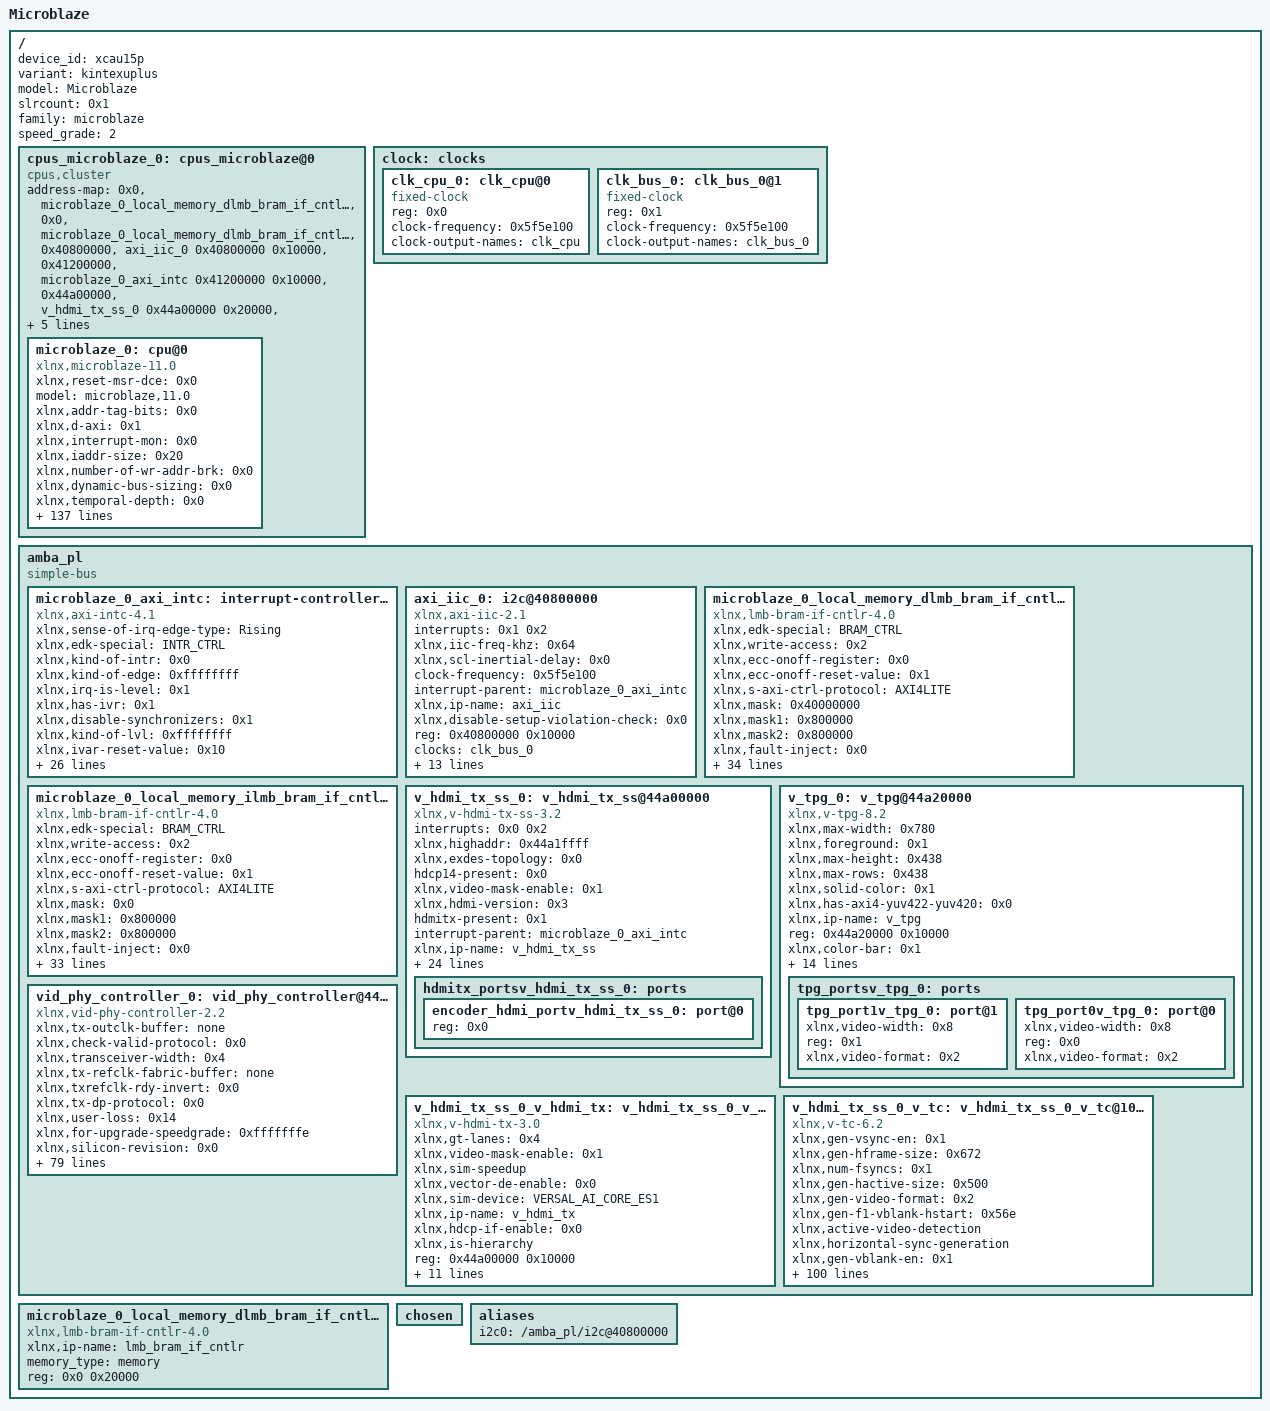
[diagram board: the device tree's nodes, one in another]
/dts-v1/;
/ {
        device_id = "xcau15p";
        #address-cells = <0x1>;
        variant = "kintexuplus";
        model = "Microblaze";
        #size-cells = <0x1>;
        slrcount = <0x1>;
        family = "microblaze";
        speed_grade = "2";

        cpus_microblaze_0: cpus_microblaze@0 {
                phandle = <0xc>;
                #cpu-mask-cells = <0x1>;
                compatible = "cpus,cluster";
                #address-cells = <0x1>;
                #size-cells = <0x0>;
                address-map = <0x0 &microblaze_0_local_memory_dlmb_bram_if_cntlr_memory 0x0 0x20000>,
                 <0x0 &microblaze_0_local_memory_dlmb_bram_if_cntlr 0x0 0x20000>,
                 <0x40800000 &axi_iic_0 0x40800000 0x10000>,
                 <0x41200000 &microblaze_0_axi_intc 0x41200000 0x10000>,
                 <0x44a00000 &v_hdmi_tx_ss_0 0x44a00000 0x20000>,
                 <0x44a20000 &v_tpg_0 0x44a20000 0x10000>,
                 <0x44a30000 &vid_phy_controller_0 0x44a30000 0x10000>,
                 <0x0 &v_hdmi_tx_ss_0_v_hdmi_tx 0x0 0x10000>,
                 <0x10000 &v_hdmi_tx_ss_0_v_tc 0x10000 0x10000>;
                #ranges-address-cells = <0x1>;
                #ranges-size-cells = <0x1>;

                microblaze_0: cpu@0 {
                        phandle = <0xd>;
                        xlnx,reset-msr-dce = <0x0>;
                        model = "microblaze,11.0";
                        xlnx,addr-tag-bits = <0x0>;
                        xlnx,d-axi = <0x1>;
                        xlnx,interrupt-mon = <0x0>;
                        xlnx,iaddr-size = <0x20>;
                        xlnx,number-of-wr-addr-brk = <0x0>;
                        xlnx,dynamic-bus-sizing = <0x0>;
                        xlnx,temporal-depth = <0x0>;
                        xlnx,use-interrupt = <0x2>;
                        xlnx,optimization = <0x0>;
                        xlnx,ip-axi-mon = <0x0>;
                        xlnx,ip-name = "microblaze";
                        d-cache-highaddr = <0x3fffffff>;
                        xlnx,dcache-force-tag-lutram = <0x0>;
                        xlnx,pc-width = <0x20>;
                        xlnx,interrupt-is-edge = <0x0>;
                        reg = <0x0>;
                        xlnx,async-interrupt = <0x1>;
                        xlnx,use-mmu = <0x0>;
                        xlnx,reset-msr-ee = <0x0>;
                        xlnx,icache-victims = <0x0>;
                        xlnx,use-reorder-instr = <0x0>;
                        xlnx,d-lmb-mon = <0x0>;
                        xlnx,d-lmb-protocol = <0x0>;
                        xlnx,ill-opcode-exception = <0x0>;
                        xlnx,dcache-always-used = <0x0>;
                        xlnx,use-div = <0x0>;
                        xlnx,dc-axi-mon = <0x0>;
                        xlnx,debug-trace-async-reset = <0x0>;
                        xlnx,trace = <0x0>;
                        xlnx,part = "xcau15p-ffvb676-2-e";
                        i-cache-baseaddr = <0x0>;
                        xlnx,use-config-reset = <0x0>;
                        xlnx,pvr = <0x0>;
                        xlnx,i-lmb-mon = <0x0>;
                        xlnx,dcache-byte-size = <0x1000>;
                        xlnx,fault-tolerant = <0x0>;
                        xlnx,family = "kintexuplus";
                        compatible = "xlnx,microblaze-11.0", "xlnx,microblaze";
                        xlnx,data-size = <0x20>;
                        xlnx,mmu-zones = <0x2>;
                        xlnx,debug-trace-size = <0x2000>;
                        xlnx,mmu-privileged-instr = <0x0>;
                        xlnx,enable-discrete-ports = <0x0>;
                        d-cache-line-size = <0x10>;
                        xlnx,d-lmb = <0x1>;
                        xlnx,sco = <0x0>;
                        xlnx,reset-msr-eip = <0x0>;
                        xlnx,debug-interface = <0x0>;
                        clock-frequency = <0x5f5e100>;
                        xlnx,use-ext-brk = <0x0>;
                        xlnx,daddr-size = <0x20>;
                        xlnx,debug-enabled = <0x1>;
                        xlnx,reset-msr-ice = <0x0>;
                        xlnx,num-sync-ff-dbg-trace-clk = <0x2>;
                        xlnx,i-lmb-protocol = <0x0>;
                        xlnx,endianness = <0x1>;
                        xlnx,fsl-exception = <0x0>;
                        i-cache-line-size = <0x10>;
                        xlnx,use-extended-fsl-instr = <0x0>;
                        xlnx,reset-msr = <0x0>;
                        xlnx,dp-axi-mon = <0x0>;
                        device_type = "cpu";
                        xlnx,branch-target-cache-size = <0x0>;
                        xlnx,dcache-use-writeback = <0x0>;
                        xlnx,div-zero-exception = <0x0>;
                        xlnx,mmu-tlb-access = <0x3>;
                        bus-handle = <&amba_pl>;
                        xlnx,cache-byte-size = <0x1000>;
                        xlnx,pvr-user2 = <0x0>;
                        xlnx,opcode-0x0-illegal = <0x0>;
                        xlnx,icache-line-len = <0x4>;
                        xlnx,ecc-use-ce-exception = <0x0>;
                        xlnx,base-vectors = <0x0>;
                        xlnx,d-lmb-has-prot = <0x0>;
                        xlnx,edk-special = "microblaze";
                        xlnx,use-dcache = <0x0>;
                        xlnx,use-barrel = <0x1>;
                        xlnx,reset-msr-bip = <0x0>;
                        xlnx,allow-dcache-wr = <0x1>;
                        xlnx,debug-external-trace = <0x0>;
                        xlnx,addr-size = <0x20>;
                        xlnx,piaddr-size = <0x20>;
                        i-cache-highaddr = <0x3fffffff>;
                        xlnx,num-sync-ff-clk-debug = <0x2>;
                        xlnx,debug-event-counters = <0x5>;
                        xlnx,fpu-exception = <0x0>;
                        xlnx,allow-icache-wr = <0x1>;
                        xlnx,g-use-exceptions = <0x0>;
                        xlnx,i-axi = <0x0>;
                        xlnx,g-template-list = <0x8>;
                        xlnx,icache-streams = <0x0>;
                        xlnx,dcache-line-len = <0x4>;
                        xlnx,num-sync-ff-clk = <0x2>;
                        xlnx,edk-iptype = "PROCESSOR";
                        xlnx,use-stack-protection = <0x0>;
                        xlnx,use-hw-mul = <0x1>;
                        xlnx,num-sync-ff-dbg-clk = <0x1>;
                        xlnx,interconnect = <0x2>;
                        xlnx,i-lmb-has-prot = <0x0>;
                        xlnx,debug-latency-counters = <0x1>;
                        i-cache-size = <0x1000>;
                        xlnx,exceptions-in-delay-slots = <0x1>;
                        xlnx,use-fpu = <0x0>;
                        xlnx,reset-msr-ie = <0x0>;
                        xlnx,edge-is-positive = <0x1>;
                        xlnx,use-pcmp-instr = <0x1>;
                        xlnx,use-icache = <0x0>;
                        d-cache-size = <0x1000>;
                        xlnx,memory-ip-list = "microblaze_0_local_memory_ilmb_bram_if_cntlr_memory", "microblaze_0_local_memory_dlmb_bram_if_cntlr_memory";
                        xlnx,async-wakeup = <0x3>;
                        xlnx,use-non-secure = <0x0>;
                        xlnx,dcache-addr-tag = <0x0>;
                        xlnx,number-of-rd-addr-brk = <0x0>;
                        d-cache-baseaddr = <0x0>;
                        xlnx,area-optimized = <0x1>;
                        xlnx,avoid-primitives = <0x0>;
                        xlnx,lockstep-slave = <0x0>;
                        xlnx,use-ext-nm-brk = <0x0>;
                        xlnx,instr-size = <0x20>;
                        interrupt-handle = <&microblaze_0_axi_intc>;
                        xlnx,icache-always-used = <0x0>;
                        xlnx,i-lmb = <0x1>;
                        xlnx,mmu-dtlb-size = <0x2>;
                        xlnx,lockstep-select = <0x0>;
                        xlnx,lmb-data-size = <0x20>;
                        xlnx,ic-axi-mon = <0x0>;
                        xlnx,enable-conversion = <0x0>;
                        xlnx,num-sync-ff-clk-irq = <0x1>;
                        xlnx,fsl-links = <0x0>;
                        timebase-frequency = <0x5f5e100>;
                        xlnx,icache-force-tag-lutram = <0x0>;
                        xlnx,dcache-data-width = <0x0>;
                        xlnx,dcache-victims = <0x0>;
                        xlnx,use-branch-target-cache = <0x0>;
                        xlnx,debug-profile-size = <0x0>;
                        xlnx,unaligned-exceptions = <0x0>;
                        xlnx,lockstep-master = <0x0>;
                        xlnx,freq = <0x5f5e100>;
                        xlnx,number-of-pc-brk = <0x1>;
                        xlnx,mmu-itlb-size = <0x1>;
                        xlnx,imprecise-exceptions = <0x0>;
                        xlnx,use-msr-instr = <0x1>;
                        xlnx,icache-data-width = <0x0>;
                        xlnx,debug-counter-width = <0x20>;
                };
        };

        clock: clocks {
                phandle = <0xe>;
                #address-cells = <0x1>;
                #size-cells = <0x0>;

                clk_cpu_0: clk_cpu@0 {
                        phandle = <0xf>;
                        compatible = "fixed-clock";
                        reg = <0x0>;
                        clock-frequency = <0x5f5e100>;
                        clock-output-names = "clk_cpu";
                        #clock-cells = <0x0>;
                };

                clk_bus_0: clk_bus_0@1 {
                        phandle = <0xb>;
                        compatible = "fixed-clock";
                        reg = <0x1>;
                        clock-frequency = <0x5f5e100>;
                        clock-output-names = "clk_bus_0";
                        #clock-cells = <0x0>;
                };
        };

        amba_pl: amba_pl {
                phandle = <0xa>;
                ranges;
                compatible = "simple-bus";
                #address-cells = <0x1>;
                #size-cells = <0x1>;

                microblaze_0_axi_intc: interrupt-controller@41200000 {
                        phandle = <0x4>;
                        #interrupt-cells = <0x2>;
                        xlnx,sense-of-irq-edge-type = "Rising";
                        xlnx,edk-special = "INTR_CTRL";
                        xlnx,kind-of-intr = <0x0>;
                        xlnx,kind-of-edge = <0xffffffff>;
                        xlnx,irq-is-level = <0x1>;
                        xlnx,has-ivr = <0x1>;
                        compatible = "xlnx,axi-intc-4.1", "xlnx,xps-intc-1.00.a";
                        xlnx,disable-synchronizers = <0x1>;
                        xlnx,kind-of-lvl = <0xffffffff>;
                        xlnx,ivar-reset-value = <0x10>;
                        xlnx,irq-active = <0x1>;
                        xlnx,en-cascade-mode = <0x0>;
                        xlnx,ip-name = "axi_intc";
                        xlnx,has-ilr = <0x0>;
                        reg = <0x41200000 0x10000>;
                        xlnx,addr-width = <0x20>;
                        xlnx,s-axi-aclk-freq-mhz = <0x64>;
                        xlnx,num-sw-intr = <0x3>;
                        xlnx,irq-connection = <0x0>;
                        xlnx,num-intr-inputs = <0x2>;
                        xlnx,has-sie = <0x1>;
                        xlnx,enable-async = <0x0>;
                        xlnx,has-cie = <0x1>;
                        xlnx,num-sync-ff = <0x2>;
                        xlnx,edk-iptype = "PERIPHERAL";
                        xlnx,mb-clk-not-connected = <0x1>;
                        xlnx,has-ipr = <0x1>;
                        xlnx,sense-of-irq-level-type = "Active_High";
                        xlnx,cascade-master = <0x0>;
                        xlnx,processor-clk-freq-mhz = <0x64>;
                        status = "okay";
                        xlnx,is-fast = <0x1>;
                        xlnx,has-fast = <0x1>;
                        xlnx,ivar-rst-val = <0x10>;
                        interrupt-controller;
                        xlnx,async-intr = <0xfffffffd>;
                        xlnx,name = "microblaze_0_axi_intc";
                };

                axi_iic_0: i2c@40800000 {
                        phandle = <0x3>;
                        interrupts = <0x1 0x2>;
                        xlnx,iic-freq-khz = <0x64>;
                        compatible = "xlnx,axi-iic-2.1", "xlnx,xps-iic-2.00.a";
                        xlnx,scl-inertial-delay = <0x0>;
                        clock-frequency = <0x5f5e100>;
                        interrupt-parent = <&microblaze_0_axi_intc>;
                        xlnx,ip-name = "axi_iic";
                        xlnx,disable-setup-violation-check = <0x0>;
                        reg = <0x40800000 0x10000>;
                        clocks = <&clk_bus_0>;
                        xlnx,gpo-width = <0x1>;
                        xlnx,edk-iptype = "PERIPHERAL";
                        xlnx,static-timing-reg-width = <0x0>;
                        xlnx,sda-level = <0x1>;
                        status = "okay";
                        xlnx,ten-bit-adr = <0x0>;
                        xlnx,default-value = <0x0>;
                        interrupt-names = "iic2intc_irpt";
                        xlnx,iic-board-interface = "Custom";
                        xlnx,timing-reg-width = <0x20>;
                        xlnx,iic-freq = <0x186a0>;
                        xlnx,smbus-pmbus-host = <0x0>;
                        xlnx,name = "axi_iic_0";
                        xlnx,axi-aclk-freq-mhz = <0x64>;
                        xlnx,sda-inertial-delay = <0x0>;
                };

                microblaze_0_local_memory_dlmb_bram_if_cntlr: lmb_bram_if_cntlr@0 {
                        phandle = <0x2>;
                        xlnx,edk-special = "BRAM_CTRL";
                        xlnx,write-access = <0x2>;
                        compatible = "xlnx,lmb-bram-if-cntlr-4.0", "xlnx,axi-bram-ctrl";
                        xlnx,ecc-onoff-register = <0x0>;
                        xlnx,ecc-onoff-reset-value = <0x1>;
                        xlnx,s-axi-ctrl-protocol = "AXI4LITE";
                        xlnx,mask = <0x40000000>;
                        xlnx,mask1 = <0x800000>;
                        xlnx,mask2 = <0x800000>;
                        xlnx,fault-inject = <0x0>;
                        xlnx,mask3 = <0x800000>;
                        xlnx,ip-name = "lmb_bram_if_cntlr";
                        xlnx,arbitration = <0x0>;
                        xlnx,num-lmb = <0x1>;
                        xlnx,mask4 = <0x800000>;
                        reg = <0x0 0x20000>;
                        xlnx,s-axi-ctrl-addr-width = <0x20>;
                        xlnx,mask5 = <0x800000>;
                        xlnx,ecc-status-registers = <0x0>;
                        xlnx,prot-cfg = <0xff>;
                        xlnx,mask6 = <0x800000>;
                        xlnx,lmb-protocol = <0x0>;
                        xlnx,ce-counter-width = <0x0>;
                        xlnx,prot-cfg1 = <0xff>;
                        xlnx,mask7 = <0x800000>;
                        xlnx,ecc = <0x0>;
                        xlnx,edk-iptype = "PERIPHERAL";
                        xlnx,prot-cfg2 = <0xff>;
                        xlnx,lmb-dwidth = <0x20>;
                        xlnx,interconnect = <0x0>;
                        xlnx,ce-failing-registers = <0x0>;
                        xlnx,prot-cfg3 = <0xff>;
                        xlnx,ue-failing-registers = <0x0>;
                        xlnx,prot-cfg4 = <0xff>;
                        xlnx,lmb-has-prot = <0x0>;
                        status = "okay";
                        xlnx,data-width = <0x20>;
                        xlnx,prot-cfg5 = <0xff>;
                        xlnx,s-axi-ctrl-data-width = <0x20>;
                        xlnx,prot-cfg6 = <0xff>;
                        xlnx,bram-awidth = <0x20>;
                        xlnx,prot-cfg7 = <0xff>;
                        xlnx,lmb-awidth = <0x20>;
                        xlnx,name = "microblaze_0_local_memory_dlmb_bram_if_cntlr";
                };

                microblaze_0_local_memory_ilmb_bram_if_cntlr: microblaze_0_local_memory_ilmb_bram_if_cntlr@0 {
                        phandle = <0x10>;
                        xlnx,edk-special = "BRAM_CTRL";
                        xlnx,write-access = <0x2>;
                        compatible = "xlnx,lmb-bram-if-cntlr-4.0", "xlnx,axi-bram-ctrl";
                        xlnx,ecc-onoff-register = <0x0>;
                        xlnx,ecc-onoff-reset-value = <0x1>;
                        xlnx,s-axi-ctrl-protocol = "AXI4LITE";
                        xlnx,mask = <0x0>;
                        xlnx,mask1 = <0x800000>;
                        xlnx,mask2 = <0x800000>;
                        xlnx,fault-inject = <0x0>;
                        xlnx,mask3 = <0x800000>;
                        xlnx,ip-name = "lmb_bram_if_cntlr";
                        xlnx,arbitration = <0x0>;
                        xlnx,num-lmb = <0x1>;
                        xlnx,mask4 = <0x800000>;
                        reg = <0x0 0x20000>;
                        xlnx,s-axi-ctrl-addr-width = <0x20>;
                        xlnx,mask5 = <0x800000>;
                        xlnx,ecc-status-registers = <0x0>;
                        xlnx,prot-cfg = <0xff>;
                        xlnx,mask6 = <0x800000>;
                        xlnx,lmb-protocol = <0x0>;
                        xlnx,ce-counter-width = <0x0>;
                        xlnx,prot-cfg1 = <0xff>;
                        xlnx,mask7 = <0x800000>;
                        xlnx,ecc = <0x0>;
                        xlnx,edk-iptype = "PERIPHERAL";
                        xlnx,prot-cfg2 = <0xff>;
                        xlnx,lmb-dwidth = <0x20>;
                        xlnx,interconnect = <0x0>;
                        xlnx,ce-failing-registers = <0x0>;
                        xlnx,prot-cfg3 = <0xff>;
                        xlnx,ue-failing-registers = <0x0>;
                        xlnx,prot-cfg4 = <0xff>;
                        xlnx,lmb-has-prot = <0x0>;
                        status = "okay";
                        xlnx,prot-cfg5 = <0xff>;
                        xlnx,s-axi-ctrl-data-width = <0x20>;
                        xlnx,prot-cfg6 = <0xff>;
                        xlnx,bram-awidth = <0x20>;
                        xlnx,prot-cfg7 = <0xff>;
                        xlnx,lmb-awidth = <0x20>;
                        xlnx,name = "microblaze_0_local_memory_ilmb_bram_if_cntlr";
                };

                v_hdmi_tx_ss_0: v_hdmi_tx_ss@44a00000 {
                        phandle = <0x5>;
                        interrupts = <0x0 0x2>;
                        compatible = "xlnx,v-hdmi-tx-ss-3.2", "xlnx,v-hdmi-tx-ss-3.1";
                        xlnx,highaddr = <0x44a1ffff>;
                        xlnx,exdes-topology = <0x0>;
                        hdcp14-present = <0x0>;
                        xlnx,video-mask-enable = <0x1>;
                        xlnx,hdmi-version = <0x3>;
                        hdmitx-present = <0x1>;
                        interrupt-parent = <&microblaze_0_axi_intc>;
                        xlnx,ip-name = "v_hdmi_tx_ss";
                        hdmitx-connected = <&v_hdmi_tx_ss_0_v_hdmi_tx>;
                        xlnx,hysteresis-level = <0xc>;
                        reg = <0x44a00000 0x20000>;
                        xlnx,addr-width = <0xa>;
                        xlnx,ch-width = <0x8>;
                        xlnx,exdes-nidru;
                        xlnx,exdes-rx-pll-selection = <0x0>;
                        xlnx,vid-interface = <0x0>;
                        xlnx,max-bits-per-component = <0x8>;
                        xlnx,exdes-tx-pll-selection = <0x6>;
                        hdcp22-present = <0x0>;
                        xlnx,add-mark-dbg = <0x0>;
                        xlnx,edk-iptype = "PERIPHERAL";
                        vtc-present = <0x1>;
                        xlnx,max-res = <0x0>;
                        xlnx,ddc2-en = <0x0>;
                        status = "okay";
                        xlnx,axi-lite-freq-hz = <0x5f5e100>;
                        vtc-connected = <&v_hdmi_tx_ss_0_v_tc>;
                        xlnx,input-pixels-per-clock = <0x4>;
                        hdcptimer-present = <0x0>;
                        interrupt-names = "irq";
                        xlnx,include-yuv420-sup;
                        xlnx,include-low-reso-vid;
                        xlnx,name = "v_hdmi_tx_ss_0";
                        xlnx,exdes-axilite-freq = <0x64>;

                        hdmitx_portsv_hdmi_tx_ss_0: ports {
                                phandle = <0x11>;
                                #address-cells = <0x1>;
                                #size-cells = <0x0>;

                                encoder_hdmi_portv_hdmi_tx_ss_0: port@0 {
                                        phandle = <0x12>;
                                        reg = <0x0>;
                                };
                        };
                };

                v_tpg_0: v_tpg@44a20000 {
                        phandle = <0x6>;
                        compatible = "xlnx,v-tpg-8.2", "xlnx,v-tpg-8.0";
                        xlnx,max-width = <0x780>;
                        xlnx,foreground = <0x1>;
                        xlnx,max-height = <0x438>;
                        xlnx,max-rows = <0x438>;
                        xlnx,solid-color = <0x1>;
                        xlnx,has-axi4-yuv422-yuv420 = <0x0>;
                        xlnx,ip-name = "v_tpg";
                        reg = <0x44a20000 0x10000>;
                        xlnx,color-bar = <0x1>;
                        xlnx,s-axi-ctrl-addr-width = <0x8>;
                        xlnx,samples-per-clock = <0x4>;
                        xlnx,max-data-width = <0x8>;
                        xlnx,has-axi4s-slave = <0x0>;
                        xlnx,ppc = <0x4>;
                        xlnx,max-cols = <0x780>;
                        xlnx,edk-iptype = "PERIPHERAL";
                        status = "okay";
                        xlnx,zone-plate = <0x1>;
                        xlnx,num-video-components = <0x3>;
                        xlnx,ramp = <0x1>;
                        xlnx,color-sweep = <0x1>;
                        xlnx,s-axi-ctrl-data-width = <0x20>;
                        xlnx,display-port = <0x1>;
                        xlnx,name = "v_tpg_0";

                        tpg_portsv_tpg_0: ports {
                                phandle = <0x13>;
                                #address-cells = <0x1>;
                                #size-cells = <0x0>;

                                tpg_port1v_tpg_0: port@1 {
                                        phandle = <0x14>;
                                        xlnx,video-width = <0x8>;
                                        reg = <0x1>;
                                        xlnx,video-format = <0x2>;
                                };

                                tpg_port0v_tpg_0: port@0 {
                                        phandle = <0x15>;
                                        xlnx,video-width = <0x8>;
                                        reg = <0x0>;
                                        xlnx,video-format = <0x2>;
                                };
                        };
                };

                vid_phy_controller_0: vid_phy_controller@44a30000 {
                        phandle = <0x7>;
                        xlnx,tx-outclk-buffer = "none";
                        xlnx,check-valid-protocol = <0x0>;
                        xlnx,transceiver-width = <0x4>;
                        xlnx,tx-refclk-fabric-buffer = "none";
                        xlnx,txrefclk-rdy-invert = <0x0>;
                        xlnx,tx-dp-protocol = <0x0>;
                        xlnx,user-loss = <0x14>;
                        xlnx,for-upgrade-speedgrade = <0xfffffffe>;
                        xlnx,silicon-revision = <0x0>;
                        xlnx,vid-phy-rx-axi4s-ch-tdata-width = <0x28>;
                        xlnx,tx-tmds-clk-buffer = "bufg";
                        xlnx,ip-name = "vid_phy_controller";
                        xlnx,rx-clk-primitive = <0x0>;
                        reg = <0x44a30000 0x10000>;
                        xlnx,drpclk-freq = <0x5f5e100>;
                        xlnx,vid-phy-status-sb-rx-tdata-width = <0x1>;
                        xlnx,hdio-rx = <0x0>;
                        xlnx,supportlevel = <0x1>;
                        xlnx,check-pll-selection = <0x0>;
                        xlnx,sub-core-name = "hdmi_tx_bd_vid_phy_controller_0_0_gtwrapper";
                        xlnx,vid-phy-axi4lite-addr-width = <0xa>;
                        xlnx,rx-outclk-buffer = "none";
                        xlnx,vid-phy-control-sb-tx-tdata-width = <0x1>;
                        compatible = "xlnx,vid-phy-controller-2.2", "xlnx,vid-phy-controller-2.1";
                        xlnx,rx-max-gt-line-rate = <0x5aa320>;
                        xlnx,tx-sb-ports;
                        xlnx,for-upgrade-architecture = "kintexuplus";
                        xlnx,hdmi-fast-switch = <0x1>;
                        xlnx,rx-video-clk-buffer = "bufg";
                        xlnx,channel-enable = "X0Y8 , X0Y9 , X0Y10";
                        xlnx,transceiver = "GTHE4";
                        xlnx,nidru-refclk-sel = <0x0>;
                        xlnx,rx-gt-line-rate = <0x5aa320>;
                        xlnx,vid-phy-tx-axi4s-ch-int-tdata-width = <0x28>;
                        xlnx,dru-refclk-fabric-buffer = "none";
                        xlnx,err-irq-en = <0x0>;
                        xlnx,vid-phy-rx-axi4s-ch-tuser-width = <0x1>;
                        xlnx,tx-protocol = <0x1>;
                        xlnx,vid-phy-status-sb-tx-tdata-width = <0x8>;
                        xlnx,hdio-tx = <0x0>;
                        status = "okay";
                        xlnx,input-pixels-per-clock = <0x4>;
                        xlnx,axi4lite-enable;
                        xlnx,axi-aclk-freq-mhz = <0x5f5e100>;
                        xlnx,name = "vid_phy_controller_0";
                        xlnx,dru-gain-g1-p = <0x10>;
                        xlnx,rx-tdata-width = <0x28>;
                        xlnx,tx-pll-selection = <0x6>;
                        xlnx,vid-phy-tx-axi4s-ch-tdata-width = <0x28>;
                        xlnx,use-oddr-for-tmds-clkout;
                        xlnx,for-upgrade-maxoptvol = <0xd5de0>;
                        xlnx,edk-iptype = "PERIPHERAL";
                        xlnx,speedgrade = <0xfffffffe>;
                        xlnx,for-upgrade-package = "ffvb676";
                        xlnx,int-hdmi-ver-cmptble = <0x3>;
                        xlnx,int-width = <0x0>;
                        xlnx,rx-sb-ports;
                        xlnx,tx-gt-ref-clock-freq = <0x129>;
                        xlnx,tx-buffer-bypass = <0x1>;
                        xlnx,nidru = <0x0>;
                        xlnx,rx-dp-protocol = <0x0>;
                        xlnx,rx-pll-selection = <0x0>;
                        xlnx,tx-tdata-width = <0x28>;
                        xlnx,transceiver-type = <0x5>;
                        xlnx,tx-max-gt-line-rate = <0x5aa320>;
                        xlnx,rx-tmds-clk-buffer = "bufg";
                        xlnx,vid-phy-rx-axi4s-ch-int-tdata-width = <0x28>;
                        xlnx,vid-phy-axi4lite-data-width = <0x20>;
                        xlnx,tx-video-clk-buffer = "bufg";
                        xlnx,for-upgrade-refvol = <0xcf850>;
                        xlnx,rx-refclk-sel = <0x1>;
                        xlnx,use-gt-ch4-hdmi = <0x0>;
                        xlnx,for-upgrade-part = "xcau15p-ffvb676-2-e";
                        xlnx,tx-refclk-sel = <0x0>;
                        xlnx,for-upgrade-device = "xcau15p";
                        xlnx,rx-protocol = <0x3>;
                        xlnx,tx-clk-primitive = <0x0>;
                        xlnx,tx-gt-line-rate = <0x5aa320>;
                        xlnx,channel-site = "X0Y8";
                        xlnx,dru-gain-g1 = <0x9>;
                        xlnx,vid-phy-tx-axi4s-ch-tuser-width = <0x1>;
                        xlnx,dru-gain-g2 = <0x4>;
                        xlnx,rx-no-of-channels = <0x3>;
                        xlnx,rx-gt-ref-clock-freq = <0x129>;
                        xlnx,vid-phy-control-sb-rx-tdata-width = <0x1>;
                        xlnx,device = "xcau15p";
                        xlnx,tx-no-of-channels = <0x3>;
                        xlnx,component-name = "hdmi_tx_bd_vid_phy_controller_0_0";
                };

                v_hdmi_tx_ss_0_v_hdmi_tx: v_hdmi_tx_ss_0_v_hdmi_tx@0 {
                        phandle = <0x8>;
                        compatible = "xlnx,v-hdmi-tx-3.0";
                        xlnx,gt-lanes = <0x4>;
                        xlnx,video-mask-enable = <0x1>;
                        xlnx,sim-speedup;
                        xlnx,vector-de-enable = <0x0>;
                        xlnx,sim-device = "VERSAL_AI_CORE_ES1";
                        xlnx,ip-name = "v_hdmi_tx";
                        xlnx,hdcp-if-enable = <0x0>;
                        xlnx,is-hierarchy;
                        reg = <0x44a00000 0x10000>;
                        xlnx,ch-width = <0x8>;
                        xlnx,pixels-per-clock = <0x4>;
                        xlnx,edk-iptype = "PERIPHERAL";
                        xlnx,num-of-intr = <0x1>;
                        xlnx,tst-dbg = <0x0>;
                        xlnx,ddc2-en = <0x0>;
                        xlnx,sim-device-en = <0x0>;
                        status = "okay";
                        xlnx,bits-per-component = <0x8>;
                        xlnx,is-versal = <0x0>;
                        xlnx,axi-lite-freq-hz = <0x5f5e100>;
                        xlnx,name = "v_hdmi_tx_ss_0_v_hdmi_tx";
                };

                v_hdmi_tx_ss_0_v_tc: v_hdmi_tx_ss_0_v_tc@10000 {
                        phandle = <0x9>;
                        xlnx,gen-vsync-en = <0x1>;
                        xlnx,gen-hframe-size = <0x672>;
                        xlnx,num-fsyncs = <0x1>;
                        xlnx,gen-hactive-size = <0x500>;
                        xlnx,gen-video-format = <0x2>;
                        xlnx,gen-f1-vblank-hstart = <0x56e>;
                        xlnx,active-video-detection;
                        xlnx,horizontal-sync-generation;
                        xlnx,gen-vblank-en = <0x1>;
                        xlnx,gen-avideo-en = <0x1>;
                        xlnx,ip-name = "v_tc";
                        xlnx,fsync-hstart10 = <0x0>;
                        xlnx,max-pixels = <0x2000>;
                        xlnx,gen-fieldid-en = <0x1>;
                        reg = <0x44a10000 0x10000>;
                        xlnx,det-vblank-en = <0x1>;
                        xlnx,fsync-hstart11 = <0x0>;
                        xlnx,fsync-hstart12 = <0x0>;
                        xlnx,pixels-per-clock = <0x4>;
                        xlnx,gen-interlaced = <0x0>;
                        xlnx,det-avideo-en = <0x1>;
                        xlnx,fsync-hstart13 = <0x0>;
                        xlnx,fsync-hstart14 = <0x0>;
                        xlnx,gen-f0-vblank-hend = <0x56e>;
                        xlnx,fsync-hstart15 = <0x0>;
                        xlnx,det-hsync-en = <0x1>;
                        xlnx,enable-generation;
                        xlnx,gen-avideo-polarity = <0x1>;
                        xlnx,max-lines-per-frame = <0x1000>;
                        xlnx,has-axi4-lite = <0x1>;
                        compatible = "xlnx,v-tc-6.2", "xlnx,bridge-v-tc-6.1";
                        xlnx,max-clocks-per-line = <0x2000>;
                        xlnx,gen-f0-vframe-size = <0x2ee>;
                        xlnx,gen-f0-vblank-hstart = <0x56e>;
                        xlnx,max-lines = <0x1000>;
                        xlnx,gen-f0-vsync-vstart = <0x2d4>;
                        xlnx,horizontal-blank-generation;
                        xlnx,gen-hsync-end = <0x596>;
                        xlnx,gen-f0-vsync-hstart = <0x56e>;
                        xlnx,gen-f1-vsync-hend = <0x56e>;
                        xlnx,vertical-blank-detection;
                        xlnx,gen-vsync-polarity = <0x1>;
                        xlnx,fsync-vstart0 = <0x0>;
                        xlnx,gen-hsync-polarity = <0x1>;
                        xlnx,fsync-vstart1 = <0x0>;
                        status = "okay";
                        xlnx,fsync-vstart2 = <0x0>;
                        xlnx,gen-hsync-start = <0x56e>;
                        xlnx,gen-f0-vsync-vend = <0x2d9>;
                        xlnx,fsync-vstart3 = <0x0>;
                        xlnx,vertical-sync-detection;
                        xlnx,frame-syncs = <0x1>;
                        xlnx,fsync-vstart4 = <0x0>;
                        xlnx,gen-vactive-size = <0x2d0>;
                        xlnx,name = "v_hdmi_tx_ss_0_v_tc";
                        xlnx,fsync-vstart5 = <0x0>;
                        xlnx,gen-achroma-en = <0x0>;
                        xlnx,fsync-vstart6 = <0x0>;
                        xlnx,det-fieldid-en = <0x0>;
                        xlnx,fsync-vstart7 = <0x0>;
                        xlnx,gen-hsync-en = <0x1>;
                        xlnx,fsync-vstart8 = <0x0>;
                        xlnx,fsync-vstart10 = <0x0>;
                        xlnx,fsync-vstart9 = <0x0>;
                        xlnx,fsync-vstart11 = <0x0>;
                        xlnx,arbitrary-res-en = [00];
                        xlnx,fsync-vstart12 = <0x0>;
                        xlnx,is-hierarchy;
                        xlnx,fsync-vstart13 = <0x0>;
                        xlnx,fsync-vstart14 = <0x0>;
                        xlnx,fsync-vstart15 = <0x0>;
                        xlnx,gen-cparity = <0x0>;
                        xlnx,edk-iptype = "PERIPHERAL";
                        xlnx,vertical-sync-generation;
                        xlnx,gen-f1-vblank-hend = <0x56e>;
                        xlnx,det-vsync-en = <0x1>;
                        xlnx,gen-vblank-polarity = <0x1>;
                        xlnx,fsync-hstart0 = <0x0>;
                        xlnx,interlace-en = <0x1>;
                        xlnx,gen-auto-switch = <0x0>;
                        xlnx,fsync-hstart1 = <0x0>;
                        xlnx,fsync-hstart2 = <0x0>;
                        xlnx,active-video-generation;
                        xlnx,fsync-hstart3 = <0x0>;
                        xlnx,fsync-hstart4 = <0x0>;
                        xlnx,horizontal-blank-detection;
                        xlnx,fsync-hstart5 = <0x0>;
                        xlnx,gen-f1-vframe-size = <0x2ee>;
                        xlnx,fsync-hstart6 = <0x0>;
                        xlnx,fsync-hstart7 = <0x0>;
                        xlnx,fsync-hstart8 = <0x0>;
                        xlnx,gen-hblank-en = <0x1>;
                        xlnx,fsync-hstart9 = <0x0>;
                        xlnx,horizontal-sync-detection;
                        xlnx,gen-f1-vsync-vend = <0x2d9>;
                        xlnx,detect-en = <0x0>;
                        xlnx,det-hblank-en = <0x1>;
                        xlnx,vid-ppc = <0x4>;
                        xlnx,has-intc-if = <0x0>;
                        xlnx,generate-en = <0x1>;
                        xlnx,gen-achroma-polarity = <0x1>;
                        xlnx,sync-en = <0x0>;
                        xlnx,det-achroma-en = <0x0>;
                        xlnx,generator;
                        xlnx,gen-f1-vsync-vstart = <0x2d4>;
                        xlnx,vertical-blank-generation;
                        xlnx,gen-hblank-polarity = <0x1>;
                        xlnx,video-mode = "720p";
                        xlnx,gen-fieldid-polarity = <0x1>;
                        xlnx,gen-f1-vsync-hstart = <0x56e>;
                        xlnx,gen-f0-vsync-hend = <0x56e>;
                };
        };

        microblaze_0_local_memory_dlmb_bram_if_cntlr_memory: memory@0 {
                phandle = <0x1>;
                compatible = "xlnx,lmb-bram-if-cntlr-4.0";
                xlnx,ip-name = "lmb_bram_if_cntlr";
                device_type = "memory";
                memory_type = "memory";
                reg = <0x0 0x20000>;
        };

        chosen {
        };

        aliases {
                i2c0 = "/amba_pl/i2c@40800000";
        };

        __symbols__ {
                cpus_microblaze_0 = "/cpus_microblaze@0";
                microblaze_0 = "/cpus_microblaze@0/cpu@0";
                clock = "/clocks";
                clk_cpu_0 = "/clocks/clk_cpu@0";
                clk_bus_0 = "/clocks/clk_bus_0@1";
                amba_pl = "/amba_pl";
                microblaze_0_axi_intc = "/amba_pl/interrupt-controller@41200000";
                axi_iic_0 = "/amba_pl/i2c@40800000";
                microblaze_0_local_memory_dlmb_bram_if_cntlr = "/amba_pl/lmb_bram_if_cntlr@0";
                microblaze_0_local_memory_ilmb_bram_if_cntlr = "/amba_pl/microblaze_0_local_memory_ilmb_bram_if_cntlr@0";
                v_hdmi_tx_ss_0 = "/amba_pl/v_hdmi_tx_ss@44a00000";
                hdmitx_portsv_hdmi_tx_ss_0 = "/amba_pl/v_hdmi_tx_ss@44a00000/ports";
                encoder_hdmi_portv_hdmi_tx_ss_0 = "/amba_pl/v_hdmi_tx_ss@44a00000/ports/port@0";
                v_tpg_0 = "/amba_pl/v_tpg@44a20000";
                tpg_portsv_tpg_0 = "/amba_pl/v_tpg@44a20000/ports";
                tpg_port1v_tpg_0 = "/amba_pl/v_tpg@44a20000/ports/port@1";
                tpg_port0v_tpg_0 = "/amba_pl/v_tpg@44a20000/ports/port@0";
                vid_phy_controller_0 = "/amba_pl/vid_phy_controller@44a30000";
                v_hdmi_tx_ss_0_v_hdmi_tx = "/amba_pl/v_hdmi_tx_ss_0_v_hdmi_tx@0";
                v_hdmi_tx_ss_0_v_tc = "/amba_pl/v_hdmi_tx_ss_0_v_tc@10000";
                microblaze_0_local_memory_dlmb_bram_if_cntlr_memory = "/memory@0";
        };
};
